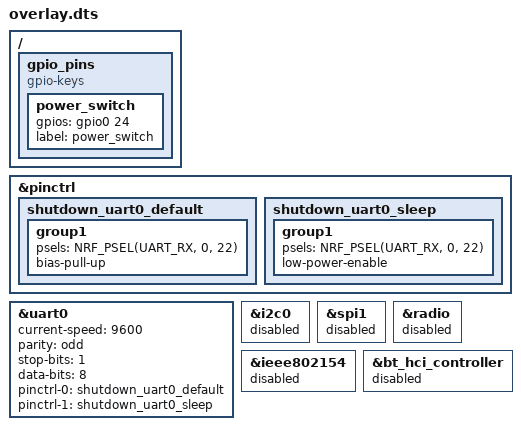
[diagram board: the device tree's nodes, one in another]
/ {
	gpio_pins {
		compatible = "gpio-keys";

		power_switch: power_switch {
			gpios = <&gpio0 24 GPIO_ACTIVE_HIGH>;
			label = "power_switch";
		};
	};
};

&pinctrl {

	shutdown_uart0_default: shutdown_uart0_default {
		group1 {
			psels = <NRF_PSEL(UART_RX, 0, 22)>;
			bias-pull-up;
		};
	};

	shutdown_uart0_sleep: shutdown_uart0_sleep {
		group1 {
			psels = <NRF_PSEL(UART_RX, 0, 22)>;
			low-power-enable;
		};
	};

};

&uart0 {
	status = "okay";

	current-speed = <9600>;
	parity = "odd";
	stop-bits = "1";
	data-bits = <8>;

	pinctrl-0 = <&shutdown_uart0_default>;
	pinctrl-1 = <&shutdown_uart0_sleep>;
	pinctrl-names = "default", "sleep";
};

&i2c0 {
	status = "disabled";
};

&spi1 {
	status = "disabled";
};

&radio {
	status = "disabled";
};

&ieee802154 {
	status = "disabled";
};

&bt_hci_controller {
	status = "disabled";
};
